LIN_description_file;
LIN_protocol_version = "2.0";
LIN_language_version = "2.0";
LIN_speed = 19.2 kbps;

Nodes {
  Master: ESP32_Master, 10 ms, 0.9 ms;
  Slaves: JOHNSON_Slave;
}

Signals {
    ACT_Master_NAD: 8, 10, ESP32_Master, JOHNSON_Slave;
    ACT_Master_Save_Prog: 2, 0, ESP32_Master, JOHNSON_Slave;
    ACT_Master_Release_Block: 2, 0, ESP32_Master, JOHNSON_Slave;
    ACT_Master_Clear_Flags: 4, 0, ESP32_Master, JOHNSON_Slave;
    ACT_Master_Coil_Holding: 2, 0, ESP32_Master, JOHNSON_Slave;
    ACT_Master_Select_Position: 2, 0, ESP32_Master, JOHNSON_Slave;
    ACT_Master_Speed: 4, 3, ESP32_Master, JOHNSON_Slave;
    ACT_Master_Desired_Position: 16, 0, ESP32_Master, JOHNSON_Slave;
    ACT_Master_Start_Position: 16, 1023, ESP32_Master, JOHNSON_Slave;
    ACT_Master_Emergency_Release: 2, 0, ESP32_Master, JOHNSON_Slave;
    ACT_Master_Emergency_Position: 2, 0, ESP32_Master, JOHNSON_Slave;
    ACT_Master_Direction: 2, 0, ESP32_Master, JOHNSON_Slave;
    ACT_Master_Stop_Mode: 2, 0, ESP32_Master, JOHNSON_Slave;

    ACT_Slave_Response_Error: 1, 0, JOHNSON_Slave, ESP32_Master;
    ACT_Slave_Overtemperature: 2, 0, JOHNSON_Slave, ESP32_Master;
    ACT_Slave_Electronic_Defect: 2, 0, JOHNSON_Slave, ESP32_Master;
    ACT_Slave_Suppy_Voltage: 2, 0, JOHNSON_Slave, ESP32_Master;
    ACT_Slave_Emergency_Run: 2, 0, JOHNSON_Slave, ESP32_Master;
    ACT_Slave_Release_Block: 2, 0, JOHNSON_Slave, ESP32_Master;
    ACT_Slave_Block_Detected: 2, 0, JOHNSON_Slave, ESP32_Master;
    ACT_Slave_Reset: 2, 0, JOHNSON_Slave, ESP32_Master;
    ACT_Slave_Coil_Holding: 2, 0, JOHNSON_Slave, ESP32_Master;
    ACT_Slave_Position_Status: 2, 0, JOHNSON_Slave, ESP32_Master;
    ACT_Slave_Speed_Status: 4, 0, JOHNSON_Slave, ESP32_Master;
    ACT_Slave_Actual_Position: 16, 0, JOHNSON_Slave, ESP32_Master;
    ACT_Slave_Traverse: 2, 0, JOHNSON_Slave, ESP32_Master;
    ACT_Slave_Holding_Torque: 2, 0, JOHNSON_Slave, ESP32_Master;
    ACT_Slave_Special_Function: 2, 0, JOHNSON_Slave, ESP32_Master;
    ACT_Slave_NAD: 8, 0, JOHNSON_Slave, ESP32_Master;
    ACT_Slave_Emergency_Release: 2, 0, JOHNSON_Slave, ESP32_Master;
    ACT_Slave_Emergency_Position: 2, 0, JOHNSON_Slave, ESP32_Master;
    ACT_Slave_Direction: 2, 0, JOHNSON_Slave, ESP32_Master;
    ACT_Slave_Stop_Mode: 2, 0, JOHNSON_Slave, ESP32_Master;

    ACT_Slave_Test_Signal: 8, 12, JOHNSON_Slave, ESP32_Master;
}

Frames {
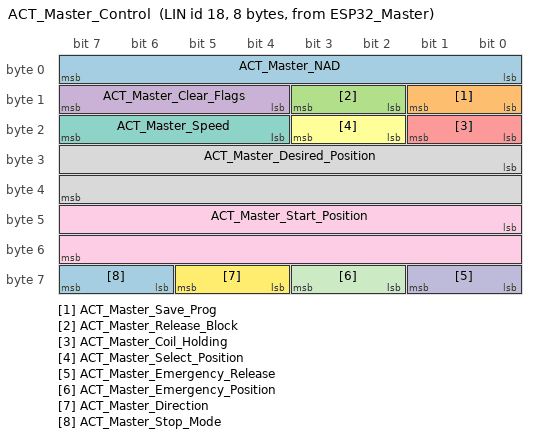
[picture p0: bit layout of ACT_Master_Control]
    ACT_Master_Control: 18, ESP32_Master, 8 {
        ACT_Master_NAD, 0;
        ACT_Master_Save_Prog, 8;
        ACT_Master_Release_Block, 10;
        ACT_Master_Clear_Flags, 12;
        ACT_Master_Coil_Holding, 16;
        ACT_Master_Select_Position, 18;
        ACT_Master_Speed, 20;
        ACT_Master_Desired_Position, 24;
        ACT_Master_Start_Position, 40;
        ACT_Master_Emergency_Release, 56;
        ACT_Master_Emergency_Position, 58;
        ACT_Master_Direction, 60;
        ACT_Master_Stop_Mode, 62;
    }
    ACT_Slave_Status: 32, JOHNSON_Slave, 8 {
        ACT_Slave_Response_Error, 0;
        ACT_Slave_Overtemperature, 2;
        ACT_Slave_Electronic_Defect, 4;
        ACT_Slave_Suppy_Voltage, 6;
        ACT_Slave_Emergency_Run, 8;
        ACT_Slave_Release_Block, 10;
        ACT_Slave_Block_Detected, 12;
        ACT_Slave_Reset, 14;
        ACT_Slave_Coil_Holding, 16;
        ACT_Slave_Position_Status, 18;
        ACT_Slave_Speed_Status, 20;
        ACT_Slave_Actual_Position, 24;
        ACT_Slave_Traverse, 40;
        ACT_Slave_Holding_Torque, 42;
        ACT_Slave_Special_Function, 44;
        ACT_Slave_NAD, 48;
        ACT_Slave_Emergency_Release, 56;
        ACT_Slave_Emergency_Position, 58;
        ACT_Slave_Direction, 60;
        ACT_Slave_Stop_Mode, 62;
    }
    ACT_Slave_Status_2: 33, JOHNSON_Slave, 8 {
        ACT_Slave_Test_Signal, 0;
    }
}

Node_attributes {
  JOHNSON_Slave {
    LIN_protocol = "2.0";
    configured_NAD = 0x01;
    product_id = 0x0000, 0x0000, 0x00;
    response_error = ACT_Slave_Response_Error;
    P2_min = 10 ms;
    ST_min = 10 ms;
    configurable_frames {
      ACT_Master_Control = 0x4015;
      ACT_Slave_Status = 0x4001;
            ACT_Slave_Status_2 = 0x4002;
    }
  }
}

Schedule_tables {
  FrameReq_Resp {
    ACT_Master_Control delay 50 ms;
    ACT_Slave_Status delay 100 ms;
  }
  DiagRequest {
    MasterReq delay 10 ms;
  }
  DiagResponse {
    SlaveResp delay 10 ms;
  }
    DiagBoth {
        MasterReq delay 20 ms;
        SlaveResp delay 20 ms;
    }
}
